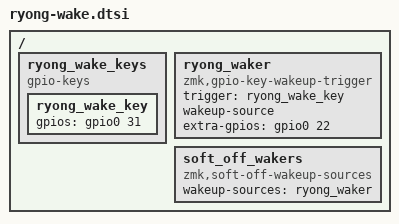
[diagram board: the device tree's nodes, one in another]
/*
 * Generated by key.ryong.com — change the wake key on the site (Firmware → edit), not by hand.
 * After a Soft Off only key position 60 (row 4, column 13) wakes the keyboard;
 * the firmware then asks for it together with a Soft Off key, held 3 s.
 */

/ {
    ryong_wake_keys {
        compatible = "gpio-keys";
        ryong_wake_key: ryong_wake_key {
            gpios = <&gpio0 31 (GPIO_ACTIVE_HIGH | GPIO_PULL_DOWN)>;
        };
    };

    ryong_waker: ryong_waker {
        compatible = "zmk,gpio-key-wakeup-trigger";
        trigger = <&ryong_wake_key>;
        wakeup-source;
        extra-gpios = <&gpio0 22 GPIO_ACTIVE_HIGH>;
    };

    soft_off_wakers {
        compatible = "zmk,soft-off-wakeup-sources";
        wakeup-sources = <&ryong_waker>;
    };
};
